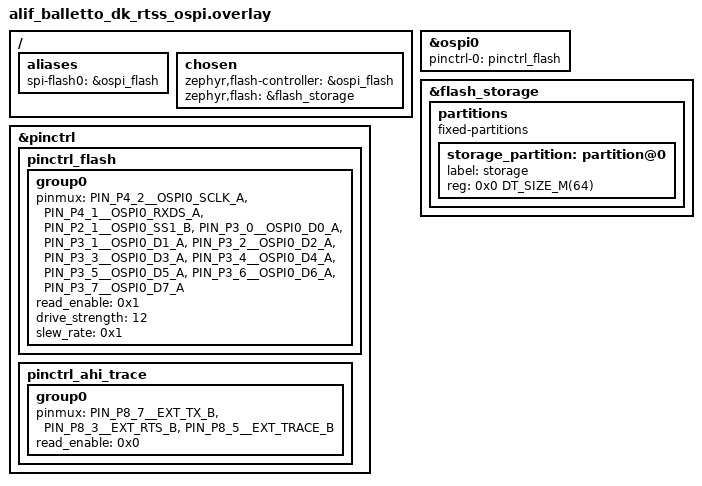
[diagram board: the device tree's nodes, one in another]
/*
 * Copyright (c) 2025 Alif Semiconductor.
 * SPDX-License-Identifier: Apache-2.0
 */

/{
	aliases {
		spi-flash0 = &ospi_flash;
	};
};

&pinctrl {
	//Flash connected with "P2_1_OSPI0_SS1_B" CS line
	pinctrl_flash: pinctrl_flash {
		group0 {
			pinmux = <PIN_P4_2__OSPI0_SCLK_A>,
				 <PIN_P4_1__OSPI0_RXDS_A>,
				 <PIN_P2_1__OSPI0_SS1_B>,
				 <PIN_P3_0__OSPI0_D0_A>,
				 <PIN_P3_1__OSPI0_D1_A>,
				 <PIN_P3_2__OSPI0_D2_A>,
				 <PIN_P3_3__OSPI0_D3_A>,
				 <PIN_P3_4__OSPI0_D4_A>,
				 <PIN_P3_5__OSPI0_D5_A>,
				 <PIN_P3_6__OSPI0_D6_A>,
				 <PIN_P3_7__OSPI0_D7_A>;
			read_enable = <0x1>;
			drive_strength = <12>;
			slew_rate = <0x1>;
		};
	};

	//Default AHI Trace pins affects OSPI-Flash pins.
	pinctrl_ahi_trace: pinctrl_ahi_trace {
		group0 {
			pinmux = <PIN_P8_7__EXT_TX_B>,
				 <PIN_P8_3__EXT_RTS_B>,
				 <PIN_P8_5__EXT_TRACE_B>;
			read_enable = < 0x0 >;
		};
	};
};

&ospi0 {
	pinctrl-0 = <&pinctrl_flash>;
	status = "okay";
};

/* Remove MRAM storage to replace flash specific storage */
/delete-node/ &mram_storage;

/* Update zephyr,flash property */
/{
	chosen {
		zephyr,flash-controller = &ospi_flash;
		zephyr,flash = &flash_storage;

		/delete-property/ zephyr,code-partition;
	};
};


/* OSPI Flash storage*/
&flash_storage {
	partitions {
		#address-cells = <1>;
		#size-cells = <1>;
		compatible = "fixed-partitions";

		/* Set 64MB of storage flash */
		storage_partition: partition@0 {
			label = "storage";
			reg = <0x0 DT_SIZE_M(64)>;
		};
	};
};
